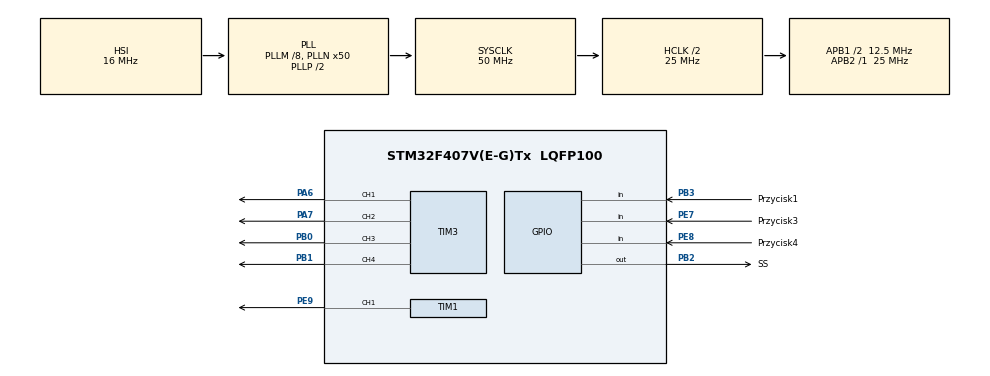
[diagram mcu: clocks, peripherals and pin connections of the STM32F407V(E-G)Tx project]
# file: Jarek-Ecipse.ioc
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Mcu.Family=STM32F4
Mcu.Name=STM32F407V(E-G)Tx
Mcu.Package=LQFP100
NVIC.PriorityGroup=NVIC_PRIORITYGROUP_4
PA6.Signal=S_TIM3_CH1
PA7.Signal=S_TIM3_CH2
PB0.Signal=S_TIM3_CH3
PB1.Signal=S_TIM3_CH4
PB2.GPIO_Label=SS
PB2.Signal=GPIO_Output
PB3.GPIO_Label=Przycisk1
PB3.Signal=GPIO_Input
PE7.GPIO_Label=Przycisk3
PE7.Signal=GPIO_Input
PE8.GPIO_Label=Przycisk4
PE8.Signal=GPIO_Input
PE9.Signal=S_TIM1_CH1
ProjectManager.HeapSize=0x200
ProjectManager.StackSize=0x400
ProjectManager.TargetToolchain=SW4STM32
RCC.48MHZClocksFreq_Value=25000000
RCC.AHBCLKDivider=RCC_SYSCLK_DIV2
RCC.AHBFreq_Value=25000000
RCC.APB1CLKDivider=RCC_HCLK_DIV2
RCC.APB1Freq_Value=12500000
RCC.APB1TimFreq_Value=25000000
RCC.APB2CLKDivider=RCC_HCLK_DIV1
RCC.APB2Freq_Value=25000000
RCC.APB2TimFreq_Value=25000000
RCC.ClockTypeHCLK=RCC_CLOCKTYPE_HCLK
RCC.ClockTypePCLK1=RCC_CLOCKTYPE_PCLK1
RCC.ClockTypePCLK2=RCC_CLOCKTYPE_PCLK2
RCC.ClockTypeSysClk=RCC_CLOCKTYPE_SYSCLK
RCC.CortexFreq_Value=25000000
RCC.Cortex_Div=SYSTICK_CLKSOURCE_HCLK
RCC.EnableExtClockForI2S=false
RCC.EnableHSE=false
RCC.EnableHSERTCDevisor=false
RCC.EnableLSE=false
RCC.EnableLSERTC=false
RCC.ExtClockEnable=false
RCC.HCLKFreq_Value=25000000
RCC.HSEState=RCC_HSE_OFF
RCC.HSE_VALUE=25000000
RCC.HSIState=RCC_HSI_ON
RCC.HSI_VALUE=16000000
RCC.I2SEnable=false
RCC.IWDGEnable=false
RCC.LSE_VALUE=32768
RCC.LSIState=RCC_LSI_OFF
RCC.MCO1OutPutEnable=false
RCC.MCO2OutPutEnable=false
RCC.OscillatorTypeHSI=RCC_OSCILLATORTYPE_HSI
RCC.PLLM=8
RCC.PLLN=50
RCC.PLLP=RCC_PLLP_DIV2
RCC.PLLSource=RCC_PLLSOURCE_HSI
RCC.PLLSourceVirtual=RCC_PLLSOURCE_HSI
RCC.PLLState=RCC_PLL_ON
RCC.RCC_MCODiv1=RCC_MCODIV_1
RCC.RCC_MCODiv2=RCC_MCODIV_1
RCC.RCC_RTC_Clock_Source_FROM_HSE=RCC_RTCCLKSOURCE_HSE_DIV2
RCC.RNGEnable=false
RCC.RTCEnable=false
RCC.SDIOEnable=false
RCC.SYSCLKFreq_VALUE=50000000
RCC.SYSCLKSource=RCC_SYSCLKSOURCE_PLLCLK
RCC.USBFSEnable=false
RCC.USBHSEnable=false
RCC.VCOOutputFreq_Value=100000000
SH.S_TIM1_CH1.0=TIM1_CH1,PWM Generation1 CH1
SH.S_TIM3_CH1.0=TIM3_CH1,PWM Generation1 CH1
SH.S_TIM3_CH2.0=TIM3_CH2,PWM Generation2 CH2
SH.S_TIM3_CH3.0=TIM3_CH3,PWM Generation3 CH3
SH.S_TIM3_CH4.0=TIM3_CH4,PWM Generation4 CH4
TIM1.Channel-PWM\ Generation1\ CH1=TIM_CHANNEL_1
TIM1.OCNIdleState_1=TIM_OCNIDLESTATE_RESET
TIM1.OCNPolarity_1=TIM_OCNPOLARITY_HIGH
TIM1.Period=999
TIM1.Prescaler=499
TIM3.Channel-PWM\ Generation1\ CH1=TIM_CHANNEL_1
TIM3.Channel-PWM\ Generation2\ CH2=TIM_CHANNEL_2
TIM3.Channel-PWM\ Generation3\ CH3=TIM_CHANNEL_3
TIM3.Channel-PWM\ Generation4\ CH4=TIM_CHANNEL_4
board=Jarek-Ecipse

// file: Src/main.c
/**
  ******************************************************************************
  * File Name          : main.c
  * Description        : Main program body
  ******************************************************************************
  *
  * COPYRIGHT(c) 2017 STMicroelectronics
  *
  * Redistribution and use in source and binary forms, with or without modification,
  * are permitted provided that the following conditions are met:
  *   1. Redistributions of source code must retain the above copyright notice,
  *      this list of conditions and the following disclaimer.
  *   2. Redistributions in binary form must reproduce the above copyright notice,
  *      this list of conditions and the following disclaimer in the documentation
  *      and/or other materials provided with the distribution.
  *   3. Neither the name of STMicroelectronics nor the names of its contributors
  *      may be used to endorse or promote products derived from this software
  *      without specific prior written permission.
  *
  * THIS SOFTWARE IS PROVIDED BY THE COPYRIGHT HOLDERS AND CONTRIBUTORS "AS IS"
  * AND ANY EXPRESS OR IMPLIED WARRANTIES, INCLUDING, BUT NOT LIMITED TO, THE
  * IMPLIED WARRANTIES OF MERCHANTABILITY AND FITNESS FOR A PARTICULAR PURPOSE ARE
  * DISCLAIMED. IN NO EVENT SHALL THE COPYRIGHT HOLDER OR CONTRIBUTORS BE LIABLE
  * FOR ANY DIRECT, INDIRECT, INCIDENTAL, SPECIAL, EXEMPLARY, OR CONSEQUENTIAL
  * DAMAGES (INCLUDING, BUT NOT LIMITED TO, PROCUREMENT OF SUBSTITUTE GOODS OR
  * SERVICES; LOSS OF USE, DATA, OR PROFITS; OR BUSINESS INTERRUPTION) HOWEVER
  * CAUSED AND ON ANY THEORY OF LIABILITY, WHETHER IN CONTRACT, STRICT LIABILITY,
  * OR TORT (INCLUDING NEGLIGENCE OR OTHERWISE) ARISING IN ANY WAY OUT OF THE USE
  * OF THIS SOFTWARE, EVEN IF ADVISED OF THE POSSIBILITY OF SUCH DAMAGE.
  *
  ******************************************************************************
  */
#include "main.h"
#include "stm32f4xx_hal.h"

TIM_HandleTypeDef htim1;
TIM_HandleTypeDef htim3;

/* USER CODE BEGIN PV */
/* Private variables ---------------------------------------------------------*/

/* USER CODE END PV */

void SystemClock_Config(void);
void Error_Handler(void);
static void MX_GPIO_Init(void);
static void MX_TIM1_Init(void);
static void MX_TIM3_Init(void);
void HAL_TIM_MspPostInit(TIM_HandleTypeDef *htim);

/* USER CODE BEGIN PFP */
/* Private function prototypes -----------------------------------------------*/

/* USER CODE END PFP */

int main(void)
{

  /* MCU Configuration----------------------------------------------------------*/

  /* Reset of all peripherals, Initializes the Flash interface and the Systick. */
  HAL_Init();

  /* Configure the system clock */
  SystemClock_Config();

  /* Initialize all configured peripherals */
  MX_GPIO_Init();
  MX_TIM1_Init();
  MX_TIM3_Init();

  /* USER CODE BEGIN 2 */
HAL_TIM_PWM_Start(&htim1,TIM_CHANNEL_1);
TIM1->CCR1=25;
  /* USER CODE END 2 */

  /* Infinite loop */
  while (1)
  {

  }

}

/** System Clock Configuration
*/
void SystemClock_Config(void)
{

  RCC_OscInitTypeDef RCC_OscInitStruct;
  RCC_ClkInitTypeDef RCC_ClkInitStruct;

    /**Configure the main internal regulator output voltage
    */
  __HAL_RCC_PWR_CLK_ENABLE();

  __HAL_PWR_VOLTAGESCALING_CONFIG(PWR_REGULATOR_VOLTAGE_SCALE1);

    /**Initializes the CPU, AHB and APB busses clocks
    */
  RCC_OscInitStruct.OscillatorType = RCC_OSCILLATORTYPE_HSI;
  RCC_OscInitStruct.HSIState = RCC_HSI_ON;
  RCC_OscInitStruct.HSICalibrationValue = 16;
  RCC_OscInitStruct.PLL.PLLState = RCC_PLL_ON;
  RCC_OscInitStruct.PLL.PLLSource = RCC_PLLSOURCE_HSI;
  RCC_OscInitStruct.PLL.PLLM = 8;
  RCC_OscInitStruct.PLL.PLLN = 50;
  RCC_OscInitStruct.PLL.PLLP = RCC_PLLP_DIV2;
  RCC_OscInitStruct.PLL.PLLQ = 4;
  if (HAL_RCC_OscConfig(&RCC_OscInitStruct) != HAL_OK)
  {
    Error_Handler();
  }

    /**Initializes the CPU, AHB and APB busses clocks
    */
  RCC_ClkInitStruct.ClockType = RCC_CLOCKTYPE_HCLK|RCC_CLOCKTYPE_SYSCLK
                              |RCC_CLOCKTYPE_PCLK1|RCC_CLOCKTYPE_PCLK2;
  RCC_ClkInitStruct.SYSCLKSource = RCC_SYSCLKSOURCE_PLLCLK;
  RCC_ClkInitStruct.AHBCLKDivider = RCC_SYSCLK_DIV2;
  RCC_ClkInitStruct.APB1CLKDivider = RCC_HCLK_DIV2;
  RCC_ClkInitStruct.APB2CLKDivider = RCC_HCLK_DIV1;

  if (HAL_RCC_ClockConfig(&RCC_ClkInitStruct, FLASH_LATENCY_0) != HAL_OK)
  {
    Error_Handler();
  }

    /**Configure the Systick interrupt time
    */
  HAL_SYSTICK_Config(HAL_RCC_GetHCLKFreq()/1000);

    /**Configure the Systick
    */
  HAL_SYSTICK_CLKSourceConfig(SYSTICK_CLKSOURCE_HCLK);

  /* SysTick_IRQn interrupt configuration */
  HAL_NVIC_SetPriority(SysTick_IRQn, 0, 0);
}

/* TIM1 init function */
static void MX_TIM1_Init(void)
{

  TIM_MasterConfigTypeDef sMasterConfig;
  TIM_OC_InitTypeDef sConfigOC;
  TIM_BreakDeadTimeConfigTypeDef sBreakDeadTimeConfig;

  htim1.Instance = TIM1;
  htim1.Init.Prescaler = 499;
  htim1.Init.CounterMode = TIM_COUNTERMODE_UP;
  htim1.Init.Period = 999;
  htim1.Init.ClockDivision = TIM_CLOCKDIVISION_DIV1;
  htim1.Init.RepetitionCounter = 0;
  if (HAL_TIM_PWM_Init(&htim1) != HAL_OK)
  {
    Error_Handler();
  }

  sMasterConfig.MasterOutputTrigger = TIM_TRGO_RESET;
  sMasterConfig.MasterSlaveMode = TIM_MASTERSLAVEMODE_DISABLE;
  if (HAL_TIMEx_MasterConfigSynchronization(&htim1, &sMasterConfig) != HAL_OK)
  {
    Error_Handler();
  }

  sConfigOC.OCMode = TIM_OCMODE_PWM1;
  sConfigOC.Pulse = 0;
  sConfigOC.OCPolarity = TIM_OCPOLARITY_HIGH;
  sConfigOC.OCNPolarity = TIM_OCNPOLARITY_HIGH;
  sConfigOC.OCFastMode = TIM_OCFAST_DISABLE;
  sConfigOC.OCIdleState = TIM_OCIDLESTATE_RESET;
  sConfigOC.OCNIdleState = TIM_OCNIDLESTATE_RESET;
  if (HAL_TIM_PWM_ConfigChannel(&htim1, &sConfigOC, TIM_CHANNEL_1) != HAL_OK)
  {
    Error_Handler();
  }

  sBreakDeadTimeConfig.OffStateRunMode = TIM_OSSR_DISABLE;
  sBreakDeadTimeConfig.OffStateIDLEMode = TIM_OSSI_DISABLE;
  sBreakDeadTimeConfig.LockLevel = TIM_LOCKLEVEL_OFF;
  sBreakDeadTimeConfig.DeadTime = 0;
  sBreakDeadTimeConfig.BreakState = TIM_BREAK_DISABLE;
  sBreakDeadTimeConfig.BreakPolarity = TIM_BREAKPOLARITY_HIGH;
  sBreakDeadTimeConfig.AutomaticOutput = TIM_AUTOMATICOUTPUT_DISABLE;
  if (HAL_TIMEx_ConfigBreakDeadTime(&htim1, &sBreakDeadTimeConfig) != HAL_OK)
  {
    Error_Handler();
  }

  HAL_TIM_MspPostInit(&htim1);

}

/* TIM3 init function */
static void MX_TIM3_Init(void)
{

  TIM_MasterConfigTypeDef sMasterConfig;
  TIM_OC_InitTypeDef sConfigOC;

  htim3.Instance = TIM3;
  htim3.Init.Prescaler = 0;
  htim3.Init.CounterMode = TIM_COUNTERMODE_UP;
  htim3.Init.Period = 0;
  htim3.Init.ClockDivision = TIM_CLOCKDIVISION_DIV1;
  if (HAL_TIM_PWM_Init(&htim3) != HAL_OK)
  {
    Error_Handler();
  }

  sMasterConfig.MasterOutputTrigger = TIM_TRGO_RESET;
  sMasterConfig.MasterSlaveMode = TIM_MASTERSLAVEMODE_DISABLE;
  if (HAL_TIMEx_MasterConfigSynchronization(&htim3, &sMasterConfig) != HAL_OK)
  {
    Error_Handler();
  }

  sConfigOC.OCMode = TIM_OCMODE_PWM1;
  sConfigOC.Pulse = 0;
  sConfigOC.OCPolarity = TIM_OCPOLARITY_HIGH;
  sConfigOC.OCFastMode = TIM_OCFAST_DISABLE;
  if (HAL_TIM_PWM_ConfigChannel(&htim3, &sConfigOC, TIM_CHANNEL_1) != HAL_OK)
  {
    Error_Handler();
  }

  if (HAL_TIM_PWM_ConfigChannel(&htim3, &sConfigOC, TIM_CHANNEL_2) != HAL_OK)
  {
    Error_Handler();
  }

  if (HAL_TIM_PWM_ConfigChannel(&htim3, &sConfigOC, TIM_CHANNEL_3) != HAL_OK)
  {
    Error_Handler();
  }

  if (HAL_TIM_PWM_ConfigChannel(&htim3, &sConfigOC, TIM_CHANNEL_4) != HAL_OK)
  {
    Error_Handler();
  }

  HAL_TIM_MspPostInit(&htim3);

}

/** Configure pins as
        * Analog
        * Input
        * Output
        * EVENT_OUT
        * EXTI
*/
static void MX_GPIO_Init(void)
{

  GPIO_InitTypeDef GPIO_InitStruct;

  /* GPIO Ports Clock Enable */
  __HAL_RCC_GPIOA_CLK_ENABLE();
  __HAL_RCC_GPIOB_CLK_ENABLE();
  __HAL_RCC_GPIOE_CLK_ENABLE();

  /*Configure GPIO pin Output Level */
  HAL_GPIO_WritePin(SS_GPIO_Port, SS_Pin, GPIO_PIN_RESET);

  /*Configure GPIO pin : SS_Pin */
  GPIO_InitStruct.Pin = SS_Pin;
  GPIO_InitStruct.Mode = GPIO_MODE_OUTPUT_PP;
  GPIO_InitStruct.Pull = GPIO_NOPULL;
  GPIO_InitStruct.Speed = GPIO_SPEED_FREQ_LOW;
  HAL_GPIO_Init(SS_GPIO_Port, &GPIO_InitStruct);

  /*Configure GPIO pins : Przycisk3_Pin Przycisk4_Pin */
  GPIO_InitStruct.Pin = Przycisk3_Pin|Przycisk4_Pin;
  GPIO_InitStruct.Mode = GPIO_MODE_INPUT;
  GPIO_InitStruct.Pull = GPIO_NOPULL;
  HAL_GPIO_Init(GPIOE, &GPIO_InitStruct);

  /*Configure GPIO pin : Przycisk1_Pin */
  GPIO_InitStruct.Pin = Przycisk1_Pin;
  GPIO_InitStruct.Mode = GPIO_MODE_INPUT;
  GPIO_InitStruct.Pull = GPIO_NOPULL;
  HAL_GPIO_Init(Przycisk1_GPIO_Port, &GPIO_InitStruct);

}

void Error_Handler(void)
{
  while(1)
  {
  }
}

/************************ (C) COPYRIGHT STMicroelectronics *****END OF FILE****/
